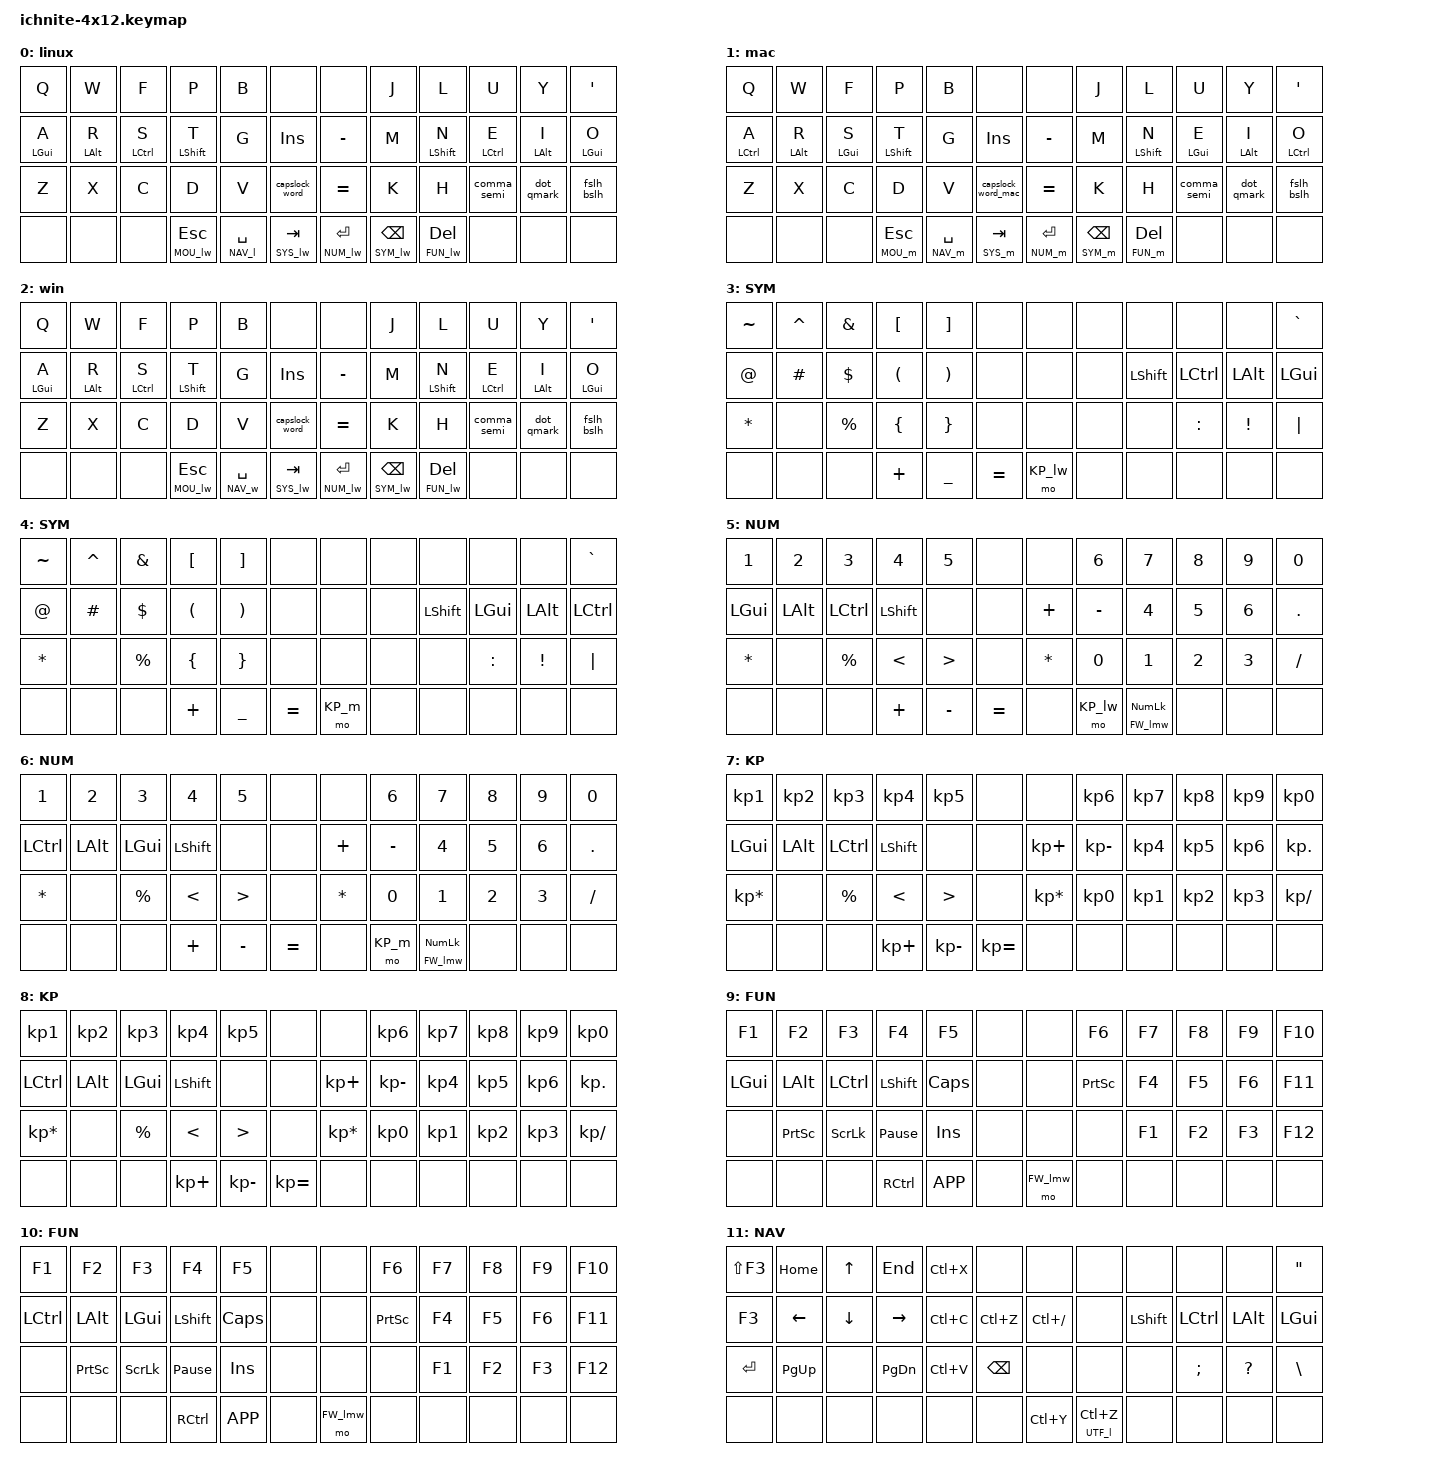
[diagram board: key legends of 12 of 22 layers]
#include <behaviors.dtsi>
#include <dt-bindings/zmk/bt.h>
#include <dt-bindings/zmk/keys.h>
#include <dt-bindings/zmk/outputs.h>
#include <dt-bindings/zmk/pointing.h>
#include "behaviors/capslock.dtsi"
#include "behaviors/base_layer.dtsi"

#define base_l 0
#define base_m 1
#define base_w 2
#define SYM_lw 3
#define SYM_m 4
#define NUM_lw 5
#define NUM_m 6
#define KP_lw 7
#define KP_m 8
#define FUN_lw 9
#define FUN_m 10
#define NAV_l 11
#define NAV_m 12
#define NAV_w 13
#define SYS_lw 14
#define SYS_m 15
#define MOU_lw 16
#define MOU_m 17
#define UTF_l 18
#define UTF_m 19
#define UTF_w 20
#define FW_lmw 21

/ {
	chosen {
		zmk,matrix_transform = &ortho4x12_transform;
	};
	keymap {
		compatible = "zmk,keymap";
		/* Colemak-DHm `base` layer
		┌────────┬────────┬─────────┬──────────┬────────────┬──────────┬────────────┬───────────┬──────────┬─────────┬────────┬────────┐
		│    q   │    w   │    f    │     p    │      b     │          │            │     j     │     l    │    u    │    y   │   '"   │
		├────────┼────────┼─────────┼──────────┼────────────┼──────────┼────────────┼───────────┼──────────┼─────────┼────────┼────────┤
		│ a ▼CMD │ r ▼ALT │ s ▼CTRL │ t ▼SHIFT │      g     │    INS   │      -     │     m     │ n ▼SHIFT │ e ▼CTRL │ i ▼ALT │ o ▼CMD │
		├────────┼────────┼─────────┼──────────┼────────────┼──────────┼────────────┼───────────┼──────────┼─────────┼────────┼────────┤
		│    z   │    x   │    c    │     d    │      v     │   CAPS   │      =     │     k     │     h    │   ,;    │   .?   │   /\   │
		├────────┼────────┼─────────┼──────────┼────────────┼──────────┼────────────┼───────────┼──────────┼─────────┼────────┼────────┤
		│        │        │         │ ESC ▼MOU │ SPACE ▼NAV │ TAB ▼SYS │ ENTER ▼NUM │ BSPC ▼SYM │ DEL ▼FUN │         │        │        │
		└────────┴────────┴─────────┴──────────┴────────────┴──────────┴────────────┴───────────┴──────────┴─────────┴────────┴────────┘ */
		base_l {
			bindings = <
			&kp Q        &kp W        &kp F         &kp P           &kp B            &none           &none             &kp J            &kp L           &kp U         &kp Y        &kp SQT
			&hrm LGUI A  &hrm LALT R  &hrm LCTRL S  &hrm LSHFT T    &kp G            &kp INS         &kp MINUS         &kp M            &hrm LSHFT N    &hrm LCTRL E  &hrm LALT I  &hrm LGUI O
			&kp Z        &kp X        &kp C         &kp D           &kp V            &capslock_word  &kp EQUAL         &kp K            &kp H           &comma_semi   &dot_qmark   &fslh_bslh
			&none        &none        &none         &lt MOU_lw ESC  &lt NAV_l SPACE  &lt SYS_lw TAB  &lt NUM_lw ENTER  &lt SYM_lw BSPC  &lt FUN_lw DEL  &none         &none        &none
			>;
			display-name = "linux";
		};
		base_m {
			bindings = <
			&kp Q         &kp W        &kp F        &kp P          &kp B            &none               &none            &kp J           &kp L          &kp U        &kp Y        &kp SQT
			&hrm LCTRL A  &hrm LALT R  &hrm LGUI S  &hrm LSHFT T   &kp G            &kp INS             &kp MINUS        &kp M           &hrm LSHFT N   &hrm LGUI E  &hrm LALT I  &hrm LCTRL O
			&kp Z         &kp X        &kp C        &kp D          &kp V            &capslock_word_mac  &kp EQUAL        &kp K           &kp H          &comma_semi  &dot_qmark   &fslh_bslh
			&none         &none        &none        &lt MOU_m ESC  &lt NAV_m SPACE  &lt SYS_m TAB       &lt NUM_m ENTER  &lt SYM_m BSPC  &lt FUN_m DEL  &none        &none        &none
			>;
			display-name = "mac";
		};
		base_w {
			bindings = <
			&kp Q        &kp W        &kp F         &kp P           &kp B            &none           &none             &kp J            &kp L           &kp U         &kp Y        &kp SQT
			&hrm LGUI A  &hrm LALT R  &hrm LCTRL S  &hrm LSHFT T    &kp G            &kp INS         &kp MINUS         &kp M            &hrm LSHFT N    &hrm LCTRL E  &hrm LALT I  &hrm LGUI O
			&kp Z        &kp X        &kp C         &kp D           &kp V            &capslock_word  &kp EQUAL         &kp K            &kp H           &comma_semi   &dot_qmark   &fslh_bslh
			&none        &none        &none         &lt MOU_lw ESC  &lt NAV_w SPACE  &lt SYS_lw TAB  &lt NUM_lw ENTER  &lt SYM_lw BSPC  &lt FUN_lw DEL  &none         &none        &none
			>;
			display-name = "win";
		};
		/* Symbols (`SYM`)
		┌───────┬───────┬───────┬───────┬───────┬───────┬───────┬───────┬───────┬───────┬───────┬───────┐
		│   ~   │   ^   │   &   │   [   │   ]   │       │       │       │       │       │       │   `   │
		├───────┼───────┼───────┼───────┼───────┼───────┼───────┼───────┼───────┼───────┼───────┼───────┤
		│   @   │   #   │   $   │   (   │   )   │       │       │       │ SHIFT │ CTRL  │  ALT  │  CMD  │
		├───────┼───────┼───────┼───────┼───────┼───────┼───────┼───────┼───────┼───────┼───────┼───────┤
		│   *   │       │   %   │   {   │   }   │       │       │       │       │   :   │   !   │ PIPE  │
		├───────┼───────┼───────┼───────┼───────┼───────┼───────┼───────┼───────┼───────┼───────┼───────┤
		│       │       │       │   +   │   _   │   =   │  ▼KP  │  XXX  │       │       │       │       │
		└───────┴───────┴───────┴───────┴───────┴───────┴───────┴───────┴───────┴───────┴───────┴───────┘ */
		SYM_lw {
			bindings = <
			&kp TILDE  &kp CARET  &kp AMPS   &kp LBKT  &kp RBKT   &none      &none      &none  &none      &none      &none     &kp GRAVE
			&kp AT     &kp HASH   &kp DLLR   &kp LPAR  &kp RPAR   &none      &none      &none  &kp LSHFT  &kp LCTRL  &kp LALT  &kp LGUI
			&kp STAR   &none      &kp PRCNT  &kp LBRC  &kp RBRC   &none      &none      &none  &none      &kp COLON  &kp EXCL  &kp PIPE
			&none      &none      &none      &kp PLUS  &kp UNDER  &kp EQUAL  &mo KP_lw  &none  &none      &none      &none     &none
			>;
			display-name = "SYM";
		};
		SYM_m {
			bindings = <
			&kp TILDE  &kp CARET  &kp AMPS   &kp LBKT  &kp RBKT   &none      &none     &none  &none      &none      &none     &kp GRAVE
			&kp AT     &kp HASH   &kp DLLR   &kp LPAR  &kp RPAR   &none      &none     &none  &kp LSHFT  &kp LGUI   &kp LALT  &kp LCTRL
			&kp STAR   &none      &kp PRCNT  &kp LBRC  &kp RBRC   &none      &none     &none  &none      &kp COLON  &kp EXCL  &kp PIPE
			&none      &none      &none      &kp PLUS  &kp UNDER  &kp EQUAL  &mo KP_m  &none  &none      &none      &none     &none
			>;
			display-name = "SYM";
		};
		/* Numerals (`NUM`)
		┌───────┬───────┬───────┬───────┬───────┬───────┬───────┬───────┬───────────┬───────┬───────┬───────┐
		│   1   │   2   │   3   │   4   │   5   │       │       │   6   │     7     │   8   │   9   │   0   │
		├───────┼───────┼───────┼───────┼───────┼───────┼───────┼───────┼───────────┼───────┼───────┼───────┤
		│  CMD  │  ALT  │ CTRL  │ SHIFT │       │       │   +   │   -   │     4     │   5   │   6   │   .   │
		├───────┼───────┼───────┼───────┼───────┼───────┼───────┼───────┼───────────┼───────┼───────┼───────┤
		│   *   │       │   %   │   <   │   >   │       │   *   │   0   │     1     │   2   │   3   │   /   │
		├───────┼───────┼───────┼───────┼───────┼───────┼───────┼───────┼───────────┼───────┼───────┼───────┤
		│       │       │       │   +   │   -   │   =   │  XXX  │  ▼KP  │ NLOCK ▼FW │       │       │       │
		└───────┴───────┴───────┴───────┴───────┴───────┴───────┴───────┴───────────┴───────┴───────┴───────┘ */
		NUM_lw {
			bindings = <
			&kp N1    &kp N2    &kp N3     &kp N4     &kp N5     &none      &none     &kp N6     &kp N7             &kp N8  &kp N9  &kp N0
			&kp LGUI  &kp LALT  &kp LCTRL  &kp LSHFT  &none      &none      &kp PLUS  &kp MINUS  &kp N4             &kp N5  &kp N6  &kp DOT
			&kp STAR  &none     &kp PRCNT  &kp LT     &kp GT     &none      &kp STAR  &kp N0     &kp N1             &kp N2  &kp N3  &kp FSLH
			&none     &none     &none      &kp PLUS   &kp MINUS  &kp EQUAL  &none     &mo KP_lw  &lt FW_lmw KP_NUM  &none   &none   &none
			>;
			display-name = "NUM";
		};
		NUM_m {
			bindings = <
			&kp N1     &kp N2    &kp N3     &kp N4     &kp N5     &none      &none     &kp N6     &kp N7             &kp N8  &kp N9  &kp N0
			&kp LCTRL  &kp LALT  &kp LGUI   &kp LSHFT  &none      &none      &kp PLUS  &kp MINUS  &kp N4             &kp N5  &kp N6  &kp DOT
			&kp STAR   &none     &kp PRCNT  &kp LT     &kp GT     &none      &kp STAR  &kp N0     &kp N1             &kp N2  &kp N3  &kp FSLH
			&none      &none     &none      &kp PLUS   &kp MINUS  &kp EQUAL  &none     &mo KP_m   &lt FW_lmw KP_NUM  &none   &none   &none
			>;
			display-name = "NUM";
		};
		/* Keypad numerals (`KP`) on `NUM+SYM` combo
		┌───────┬───────┬───────┬───────┬───────┬───────┬───────┬───────┬───────┬───────┬───────┬───────┐
		│  KP1  │  KP2  │  KP3  │  KP4  │  KP5  │       │       │  KP6  │  KP7  │  KP8  │  KP9  │  KP0  │
		├───────┼───────┼───────┼───────┼───────┼───────┼───────┼───────┼───────┼───────┼───────┼───────┤
		│  CMD  │  ALT  │ CTRL  │ SHIFT │       │       │  KP+  │  KP-  │  KP4  │  KP5  │  KP6  │  KP.  │
		├───────┼───────┼───────┼───────┼───────┼───────┼───────┼───────┼───────┼───────┼───────┼───────┤
		│  KP*  │       │   %   │   <   │   >   │       │  KP*  │  KP0  │  KP1  │  KP2  │  KP3  │  KP/  │
		├───────┼───────┼───────┼───────┼───────┼───────┼───────┼───────┼───────┼───────┼───────┼───────┤
		│       │       │       │  KP+  │  KP-  │  KP=  │  XXX  │  XXX  │       │       │       │       │
		└───────┴───────┴───────┴───────┴───────┴───────┴───────┴───────┴───────┴───────┴───────┴───────┘ */
		KP_lw {
			bindings = <
			&kp KP_N1        &kp KP_N2  &kp KP_N3  &kp KP_N4    &kp KP_N5     &none         &none            &kp KP_N6     &kp KP_N7  &kp KP_N8  &kp KP_N9  &kp KP_N0
			&kp LGUI         &kp LALT   &kp LCTRL  &kp LSHFT    &none         &none         &kp KP_PLUS      &kp KP_MINUS  &kp KP_N4  &kp KP_N5  &kp KP_N6  &kp KP_DOT
			&kp KP_MULTIPLY  &none      &kp PRCNT  &kp LT       &kp GT        &none         &kp KP_MULTIPLY  &kp KP_N0     &kp KP_N1  &kp KP_N2  &kp KP_N3  &kp KP_SLASH
			&none            &none      &none      &kp KP_PLUS  &kp KP_MINUS  &kp KP_EQUAL  &none            &none         &none      &none      &none      &none
			>;
			display-name = "KP";
		};
		KP_m {
			bindings = <
			&kp KP_N1        &kp KP_N2  &kp KP_N3  &kp KP_N4    &kp KP_N5     &none         &none            &kp KP_N6     &kp KP_N7  &kp KP_N8  &kp KP_N9  &kp KP_N0
			&kp LCTRL        &kp LALT   &kp LGUI   &kp LSHFT    &none         &none         &kp KP_PLUS      &kp KP_MINUS  &kp KP_N4  &kp KP_N5  &kp KP_N6  &kp KP_DOT
			&kp KP_MULTIPLY  &none      &kp PRCNT  &kp LT       &kp GT        &none         &kp KP_MULTIPLY  &kp KP_N0     &kp KP_N1  &kp KP_N2  &kp KP_N3  &kp KP_SLASH
			&none            &none      &none      &kp KP_PLUS  &kp KP_MINUS  &kp KP_EQUAL  &none            &none         &none      &none      &none      &none
			>;
			display-name = "KP";
		};
		/* Function keys (`FUN`)
		┌───────┬───────┬───────┬───────┬───────┬───────┬───────┬───────┬───────┬───────┬───────┬───────┐
		│  F1   │  F2   │  F3   │  F4   │  F5   │       │       │  F6   │  F7   │  F8   │  F9   │  F10  │
		├───────┼───────┼───────┼───────┼───────┼───────┼───────┼───────┼───────┼───────┼───────┼───────┤
		│  CMD  │  ALT  │ CTRL  │ SHIFT │ CLOCK │       │       │ PSCR  │  F4   │  F5   │  F6   │  F11  │
		├───────┼───────┼───────┼───────┼───────┼───────┼───────┼───────┼───────┼───────┼───────┼───────┤
		│       │ PSCR  │ SLOCK │ BREAK │  INS  │       │       │       │  F1   │  F2   │  F3   │  F12  │
		├───────┼───────┼───────┼───────┼───────┼───────┼───────┼───────┼───────┼───────┼───────┼───────┤
		│       │       │       │ rCTRL │  APP  │       │  ▼FW  │       │  XXX  │       │       │       │
		└───────┴───────┴───────┴───────┴───────┴───────┴───────┴───────┴───────┴───────┴───────┴───────┘ */
		FUN_lw {
			bindings = <
			&kp F1    &kp F2     &kp F3     &kp F4           &kp F5     &none  &none       &kp F6     &kp F7  &kp F8  &kp F9  &kp F10
			&kp LGUI  &kp LALT   &kp LCTRL  &kp LSHFT        &kp CLCK   &none  &none       &kp PSCRN  &kp F4  &kp F5  &kp F6  &kp F11
			&none     &kp PSCRN  &kp SLCK   &kp PAUSE_BREAK  &kp INS    &none  &none       &none      &kp F1  &kp F2  &kp F3  &kp F12
			&none     &none      &none      &kp RCTRL        &kp K_APP  &none  &mo FW_lmw  &none      &none   &none   &none   &none
			>;
			display-name = "FUN";
		};
		FUN_m {
			bindings = <
			&kp F1     &kp F2     &kp F3    &kp F4           &kp F5     &none  &none       &kp F6     &kp F7  &kp F8  &kp F9  &kp F10
			&kp LCTRL  &kp LALT   &kp LGUI  &kp LSHFT        &kp CLCK   &none  &none       &kp PSCRN  &kp F4  &kp F5  &kp F6  &kp F11
			&none      &kp PSCRN  &kp SLCK  &kp PAUSE_BREAK  &kp INS    &none  &none       &none      &kp F1  &kp F2  &kp F3  &kp F12
			&none      &none      &none     &kp RCTRL        &kp K_APP  &none  &mo FW_lmw  &none      &none   &none   &none   &none
			>;
			display-name = "FUN";
		};
		/* Navigation (`NAV`)
		┌───────┬───────┬───────┬───────┬───────┬───────┬─────────┬───────────┬───────┬───────┬───────┬───────┐
		│ FIND- │ HOME  │  UP   │  END  │  CUT  │       │         │           │       │       │       │   "   │
		├───────┼───────┼───────┼───────┼───────┼───────┼─────────┼───────────┼───────┼───────┼───────┼───────┤
		│ FIND+ │ LEFT  │ DOWN  │ RIGHT │ COPY  │ UNDO  │ COMMENT │           │ SHIFT │ CTRL  │  ALT  │  CMD  │
		├───────┼───────┼───────┼───────┼───────┼───────┼─────────┼───────────┼───────┼───────┼───────┼───────┤
		│ ENTER │ PG_UP │       │ PG_DN │ PASTE │ BSPC  │         │           │       │   ;   │   ?   │   \   │
		├───────┼───────┼───────┼───────┼───────┼───────┼─────────┼───────────┼───────┼───────┼───────┼───────┤
		│       │       │       │       │  XXX  │       │  REDO   │ UNDO ▼UTF │       │       │       │       │
		└───────┴───────┴───────┴───────┴───────┴───────┴─────────┴───────────┴───────┴───────┴───────┴───────┘ */
		NAV_l {
			bindings = <
			&kp LS(F3)  &kp HOME   &kp UP    &kp END    &kp LC(X)  &none      &none         &none            &none      &none      &none      &kp DQT
			&kp F3      &kp LEFT   &kp DOWN  &kp RIGHT  &kp LC(C)  &kp LC(Z)  &kp LC(FSLH)  &none            &kp LSHFT  &kp LCTRL  &kp LALT   &kp LGUI
			&kp ENTER   &kp PG_UP  &none     &kp PG_DN  &kp LC(V)  &kp BSPC   &none         &none            &none      &kp SEMI   &kp QMARK  &kp BSLH
			&none       &none      &none     &none      &none      &none      &kp LC(Y)     &lt UTF_l LC(Z)  &none      &none      &none      &none
			>;
			display-name = "NAV";
		};
		NAV_m {
			bindings = <
			&kp LS(LG(G))  &kp HOME   &kp UP    &kp END    &kp LG(X)  &none      &none         &none            &none      &none     &none      &kp DQT
			&kp LG(G)      &kp LEFT   &kp DOWN  &kp RIGHT  &kp LG(C)  &kp LG(Z)  &kp LG(FSLH)  &none            &kp LSHFT  &kp LGUI  &kp LALT   &kp LCTRL
			&kp ENTER      &kp PG_UP  &none     &kp PG_DN  &kp LG(V)  &kp BSPC   &none         &none            &none      &kp SEMI  &kp QMARK  &kp BSLH
			&none          &none      &none     &none      &none      &none      &kp LG(Y)     &lt UTF_m LG(Z)  &none      &none     &none      &none
			>;
			display-name = "NAV";
		};
		NAV_w {
			bindings = <
			&kp LS(F3)  &kp HOME   &kp UP    &kp END    &kp LC(X)  &none      &none         &none            &none      &none      &none      &kp DQT
			&kp F3      &kp LEFT   &kp DOWN  &kp RIGHT  &kp LC(C)  &kp LC(Z)  &kp LC(FSLH)  &none            &kp LSHFT  &kp LCTRL  &kp LALT   &kp LGUI
			&kp ENTER   &kp PG_UP  &none     &kp PG_DN  &kp LC(V)  &kp BSPC   &none         &none            &none      &kp SEMI   &kp QMARK  &kp BSLH
			&none       &none      &none     &none      &none      &none      &kp LC(Y)     &lt UTF_w LC(Z)  &none      &none      &none      &none
			>;
			display-name = "NAV";
		};
		/* System/media keys (`SYS`)
		┌───────┬───────┬───────┬───────┬────────┬───────┬───────┬───────┬───────┬───────┬───────┬───────┐
		│ BRI+  │  RWD  │ VOL+  │  FFW  │   WWW  │       │       │       │       │       │       │       │
		├───────┼───────┼───────┼───────┼────────┼───────┼───────┼───────┼───────┼───────┼───────┼───────┤
		│ BRI-  │ STOP  │ VOL-  │ PLAY  │ MYCOMP │  F15  │  F17  │       │ SHIFT │ CTRL  │  ALT  │  CMD  │
		├───────┼───────┼───────┼───────┼────────┼───────┼───────┼───────┼───────┼───────┼───────┼───────┤
		│       │ PREV  │ MUTE  │ NEXT  │  CALC  │  F16  │  F18  │       │       │       │       │       │
		├───────┼───────┼───────┼───────┼────────┼───────┼───────┼───────┼───────┼───────┼───────┼───────┤
		│       │       │       │  ▼FW  │        │  XXX  │       │       │       │       │       │       │
		└───────┴───────┴───────┴───────┴────────┴───────┴───────┴───────┴───────┴───────┴───────┴───────┘ */
		SYS_lw {
			bindings = <
			&kp C_BRI_UP  &kp C_RW    &kp C_VOL_UP  &kp C_FF          &kp C_AL_WWW          &none    &none    &none  &none      &none      &none     &none
			&kp C_BRI_DN  &kp C_STOP  &kp C_VOL_DN  &kp C_PLAY_PAUSE  &kp C_AL_MY_COMPUTER  &kp F15  &kp F17  &none  &kp LSHFT  &kp LCTRL  &kp LALT  &kp LGUI
			&none         &kp C_PREV  &kp C_MUTE    &kp C_NEXT        &kp C_AL_CALCULATOR   &kp F16  &kp F18  &none  &none      &none      &none     &none
			&none         &none       &none         &mo FW_lmw        &none                 &none    &none    &none  &none      &none      &none     &none
			>;
			display-name = "SYS";
		};
		SYS_m {
			bindings = <
			&kp C_BRI_UP  &kp C_RW    &kp C_VOL_UP  &kp C_FF          &kp C_AL_WWW          &none    &none    &none  &none      &none     &none     &none
			&kp C_BRI_DN  &kp C_STOP  &kp C_VOL_DN  &kp C_PLAY_PAUSE  &kp C_AL_MY_COMPUTER  &kp F15  &kp F17  &none  &kp LSHFT  &kp LGUI  &kp LALT  &kp LCTRL
			&none         &kp C_PREV  &kp C_MUTE    &kp C_NEXT        &kp C_AL_CALCULATOR   &kp F16  &kp F18  &none  &none      &none     &none     &none
			&none         &none       &none         &mo FW_lmw        &none                 &none    &none    &none  &none      &none     &none     &none
			>;
			display-name = "SYS";
		};
		/* Mouse Emulation (`MOU`)
		┌───────┬───────┬───────┬───────┬───────┬───────┬───────┬───────┬───────┬───────┬───────┬───────┐
		│ MB_2  │       │ MM_U  │       │       │       │       │       │       │       │       │       │
		├───────┼───────┼───────┼───────┼───────┼───────┼───────┼───────┼───────┼───────┼───────┼───────┤
		│ MB_1  │ MM_L  │ MM_D  │ MM_R  │       │       │       │       │ SHIFT │ CTRL  │  ALT  │  CMD  │
		├───────┼───────┼───────┼───────┼───────┼───────┼───────┼───────┼───────┼───────┼───────┼───────┤
		│ MB_3  │       │       │       │       │       │       │       │       │       │       │       │
		├───────┼───────┼───────┼───────┼───────┼───────┼───────┼───────┼───────┼───────┼───────┼───────┤
		│       │       │       │  XXX  │       │  ▼FW  │       │       │       │       │       │       │
		└───────┴───────┴───────┴───────┴───────┴───────┴───────┴───────┴───────┴───────┴───────┴───────┘ */
		MOU_lw {
			bindings = <
			&mkp MB2  &none           &mmv MOVE_UP    &none            &none  &none       &none  &none  &none      &none      &none     &none
			&mkp MB1  &mmv MOVE_LEFT  &mmv MOVE_DOWN  &mmv MOVE_RIGHT  &none  &none       &none  &none  &kp LSHFT  &kp LCTRL  &kp LALT  &kp LGUI
			&mkp MB3  &none           &none           &none            &none  &none       &none  &none  &none      &none      &none     &none
			&none     &none           &none           &none            &none  &mo FW_lmw  &none  &none  &none      &none      &none     &none
			>;
			display-name = "MOU";
		};
		MOU_m {
			bindings = <
			&mkp MB2  &none           &mmv MOVE_UP    &none            &none  &none       &none  &none  &none      &none     &none     &none
			&mkp MB1  &mmv MOVE_LEFT  &mmv MOVE_DOWN  &mmv MOVE_RIGHT  &none  &none       &none  &none  &kp LSHFT  &kp LGUI  &kp LALT  &kp LCTRL
			&mkp MB3  &none           &none           &none            &none  &none       &none  &none  &none      &none     &none     &none
			&none     &none           &none           &none            &none  &mo FW_lmw  &none  &none  &none      &none     &none     &none
			>;
			display-name = "MOU";
		};
		/* Unicode Symbols (`UTF`) on `NAV>SYM`
		┌───────┬───────┬───────┬───────┬───────┬───────┬───────┬───────┬───────┬───────┬───────┬───────┐
		│   ≈   │       │       │   √   │   ∛   │       │       │       │   μ   │   Δ   │   ε   │       │
		├───────┼───────┼───────┼───────┼───────┼───────┼───────┼───────┼───────┼───────┼───────┼───────┤
		│   ∞   │   €   │       │   ²   │   ³   │       │       │       │   π   │   φ   │   θ   │       │
		├───────┼───────┼───────┼───────┼───────┼───────┼───────┼───────┼───────┼───────┼───────┼───────┤
		│   ×   │       │   °   │   ≤   │   ≥   │       │       │   λ   │   α   │   β   │   ¿   │   ÷   │
		├───────┼───────┼───────┼───────┼───────┼───────┼───────┼───────┼───────┼───────┼───────┼───────┤
		│       │       │       │   ±   │  XXX  │   ≠   │       │       │  XXX  │       │       │       │
		└───────┴───────┴───────┴───────┴───────┴───────┴───────┴───────┴───────┴───────┴───────┴───────┘ */
		UTF_l {
			bindings = <
			&u2248_L  &none     &none     &u221a_L  &u221b_L  &none     &none  &none     &u03bc_L  &u0394_L  &u03b5_L  &none
			&u221e_L  &u20ac_L  &none     &u00b2_L  &u00b3_L  &none     &none  &none     &u03c0_L  &u03c6_L  &u03b8_L  &none
			&u00d7_L  &none     &u00b0_L  &u2264_L  &u2265_L  &none     &none  &u03bb_L  &u03b1_L  &u03b2_L  &u00bf_L  &u00f7_L
			&none     &none     &none     &u00b1_L  &none     &u2260_L  &none  &none     &none     &none     &none     &none
			>;
			display-name = "UTF";
		};
		UTF_m {
			bindings = <
			&u2248_M  &none     &none     &u221a_M  &u221b_M  &none     &none  &none     &u03bc_M  &u0394_M  &u03b5_M  &none
			&u221e_M  &u20ac_M  &none     &u00b2_M  &u00b3_M  &none     &none  &none     &u03c0_M  &u03c6_M  &u03b8_M  &none
			&u00d7_M  &none     &u00b0_M  &u2264_M  &u2265_M  &none     &none  &u03bb_M  &u03b1_M  &u03b2_M  &u00bf_M  &u00f7_M
			&none     &none     &none     &u00b1_M  &none     &u2260_M  &none  &none     &none     &none     &none     &none
			>;
			display-name = "UTF";
		};
		UTF_w {
			bindings = <
			&u2248_W  &none     &none     &u221a_W  &u221b_W  &none     &none  &none     &u03bc_W  &u0394_W  &u03b5_W  &none
			&u221e_W  &u20ac_W  &none     &u00b2_W  &u00b3_W  &none     &none  &none     &u03c0_W  &u03c6_W  &u03b8_W  &none
			&u00d7_W  &none     &u00b0_W  &u2264_W  &u2265_W  &none     &none  &u03bb_W  &u03b1_W  &u03b2_W  &u00bf_W  &u00f7_W
			&none     &none     &none     &u00b1_W  &none     &u2260_W  &none  &none     &none     &none     &none     &none
			>;
			display-name = "UTF";
		};
		/* Firmware (`FW`) on `NUM+FUN` or `MOU+SYS` combo
		┌───────┬───────┬───────┬────────┬───────┬───────┬───────┬───────┬───────┬───────┬───────┬───────┐
		│  BT1  │  BT2  │  BT3  │   BT4  │  BT5  │       │       │       │       │       │       │  USB  │
		├───────┼───────┼───────┼────────┼───────┼───────┼───────┼───────┼───────┼───────┼───────┼───────┤
		│       │ @win  │ @mac  │ @linux │       │       │       │       │  BT4  │  BT5  │       │       │
		├───────┼───────┼───────┼────────┼───────┼───────┼───────┼───────┼───────┼───────┼───────┼───────┤
		│       │       │       │        │       │       │       │  USB  │  BT1  │  BT2  │  BT3  │       │
		├───────┼───────┼───────┼────────┼───────┼───────┼───────┼───────┼───────┼───────┼───────┼───────┤
		│       │       │       │        │ BOOTL │       │       │ BOOTL │       │       │       │       │
		└───────┴───────┴───────┴────────┴───────┴───────┴───────┴───────┴───────┴───────┴───────┴───────┘ */
		FW_lmw {
			bindings = <
			&bt1   &bt2          &bt3          &bt4          &bt5    &none  &none  &none         &none  &none  &none  &out OUT_USB
			&none  &base base_w  &base base_m  &base base_l  &none   &none  &none  &none         &bt4   &bt5   &none  &none
			&none  &none         &none         &none         &none   &none  &none  &out OUT_USB  &bt1   &bt2   &bt3   &none
			&none  &none         &none         &none         &bootl  &none  &none  &bootl        &none  &none  &none  &none
			>;
			display-name = "FW";
		};
	};
	behaviors {
		hrm: modtap {
			compatible = "zmk,behavior-hold-tap";
			#binding-cells = <2>;
			bindings = <&kp>, <&kp>;
		};
		comma_semi: comma_semi {
			compatible = "zmk,behavior-mod-morph";
			#binding-cells = <0>;
			bindings = <&kp COMMA>, <&kp SEMI>;
			mods = <(MOD_LSFT|MOD_RSFT)>;
		};
		dot_qmark: dot_qmark {
			compatible = "zmk,behavior-mod-morph";
			#binding-cells = <0>;
			bindings = <&kp DOT>, <&kp QMARK>;
			mods = <(MOD_LSFT|MOD_RSFT)>;
		};
		fslh_bslh: fslh_bslh {
			compatible = "zmk,behavior-mod-morph";
			#binding-cells = <0>;
			bindings = <&kp FSLH>, <&kp BSLH>;
			mods = <(MOD_LSFT|MOD_RSFT)>;
		};
		
		#define _F(x) x
		#define _KP(x) x
		#define _BINDING_CELLS _F(#)binding-cells
		#define UTF8_MACROS(name, C1, C2, C3, C4) \
		    name##_L: name##_L { \
		        compatible = "zmk,behavior-macro"; \
		        _BINDING_CELLS = <0>; \
		        bindings = <&macro_tap &kp LC(LS(U)) &kp C1 &kp C1 &kp C3 &kp C4 &kp SPACE>; \
		        tap-ms = <30>; \
		        wait-ms = <0>; \
		    }; \
		    name##_M: name##_M { \
		        compatible = "zmk,behavior-macro"; \
		        _BINDING_CELLS = <0>; \
		        bindings = <&macro_press &kp LALT>, <&macro_tap &kp C1 &kp C1 &kp C3 &kp C4>, <&macro_release &kp LALT>; \
		        tap-ms = <30>; \
		        wait-ms = <30>; \
		    }; \
		    name##_W: name##_W { \
		        compatible = "zmk,behavior-macro"; \
		        _BINDING_CELLS = <0>; \
		        bindings = <&macro_tap &kp RALT &kp U &kp C1 &kp C1 &kp C3 &kp C4 &kp RET> ; \
		    };
		UTF8_MACROS(u2248 /* ≈ */, N2, N2, N4, N8)
		UTF8_MACROS(u221a /* √ */, N2, N2, N1, A)
		UTF8_MACROS(u221b /* ∛ */, N2, N2, N1, B)
		UTF8_MACROS(u03bc /* μ */, N0, N3, B, C)
		UTF8_MACROS(u0394 /* Δ */, N0, N3, N9, N4)
		UTF8_MACROS(u03b5 /* ε */, N0, N3, B, N5)
		UTF8_MACROS(u221e /* ∞ */, N2, N2, N1, E)
		UTF8_MACROS(u20ac /* € */, N2, N0, A, C)
		UTF8_MACROS(u00b2 /* ² */, N0, N0, B, N2)
		UTF8_MACROS(u00b3 /* ³ */, N0, N0, B, N3)
		UTF8_MACROS(u03c0 /* π */, N0, N3, C, N0)
		UTF8_MACROS(u03c6 /* φ */, N0, N3, C, N6)
		UTF8_MACROS(u03b8 /* θ */, N0, N3, B, N8)
		UTF8_MACROS(u00d7 /* × */, N0, N0, D, N7)
		UTF8_MACROS(u00b0 /* ° */, N0, N0, B, N0)
		UTF8_MACROS(u2264 /* ≤ */, N2, N2, N6, N4)
		UTF8_MACROS(u2265 /* ≥ */, N2, N2, N6, N5)
		UTF8_MACROS(u03bb /* λ */, N0, N3, B, B)
		UTF8_MACROS(u03b1 /* α */, N0, N3, B, N1)
		UTF8_MACROS(u03b2 /* β */, N0, N3, B, N2)
		UTF8_MACROS(u00bf /* ¿ */, N0, N0, B, F)
		UTF8_MACROS(u00f7 /* ÷ */, N0, N0, F, N7)
		UTF8_MACROS(u00b1 /* ± */, N0, N0, B, N1)
		UTF8_MACROS(u2260 /* ≠ */, N2, N2, N6, N0)
		btsel: btsel {
			compatible = "zmk,behavior-macro-one-param";
			#binding-cells = <1>;
			bindings = <&macro_param_1to2>, <&bt BT_SEL MACRO_PLACEHOLDER>, <&out OUT_BLE>;
		};
		bt1: bt1 {
			compatible = "zmk,behavior-tap-dance";
			#binding-cells = <0>;
			tapping-term-ms = <200>;
			bindings = <&btsel 0>, <&bt BT_DISC 0>, <&bt BT_CLR>;
		};
		bt2: bt2 {
			compatible = "zmk,behavior-tap-dance";
			#binding-cells = <0>;
			tapping-term-ms = <200>;
			bindings = <&btsel 1>, <&bt BT_DISC 1>, <&bt BT_CLR>;
		};
		bt3: bt3 {
			compatible = "zmk,behavior-tap-dance";
			#binding-cells = <0>;
			tapping-term-ms = <200>;
			bindings = <&btsel 2>, <&bt BT_DISC 2>, <&bt BT_CLR>;
		};
		bt4: bt4 {
			compatible = "zmk,behavior-tap-dance";
			#binding-cells = <0>;
			tapping-term-ms = <200>;
			bindings = <&btsel 3>, <&bt BT_DISC 3>, <&bt BT_CLR>;
		};
		bt5: bt5 {
			compatible = "zmk,behavior-tap-dance";
			#binding-cells = <0>;
			tapping-term-ms = <200>;
			bindings = <&btsel 4>, <&bt BT_DISC 4>, <&bt BT_CLR>;
		};
		bootl: bootl {
			compatible = "zmk,behavior-tap-dance";
			#binding-cells = <0>;
			tapping-term-ms = <200>;
			bindings = <&trans>, <&bootloader>;
		};
	};
};

&lt {
	flavor = "hold-preferred";
	tapping-term-ms = <150>;
	quick-tap-ms = <200>;
};

&hrm {
	flavor = "tap-preferred";
	tapping-term-ms = <150>;
	quick-tap-ms = <200>;
};
